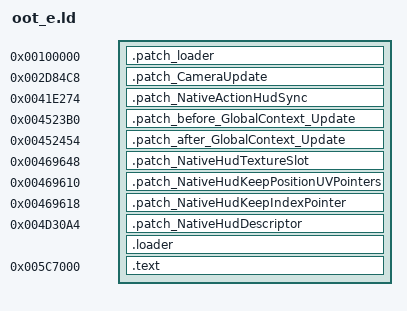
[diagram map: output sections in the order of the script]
OUTPUT_FORMAT("elf32-littlearm", "elf32-littlearm", "elf32-littlearm")
OUTPUT_ARCH(arm)
ENTRY(loader_patch)
SECTIONS
{
	. = 0x100000;
	.patch_loader 0x100000 : {
		*(.patch_loader)
	}

	.patch_CameraUpdate 0x2D84C8 : {
	    * (.patch_CameraUpdate)
	}

	.patch_NativeActionHudSync 0x41E274 : {
		*(.patch_NativeActionHudSync)
	}

	.patch_before_GlobalContext_Update 0x4523B0 : {
		*(.patch_before_GlobalContext_Update)
	}

	.patch_after_GlobalContext_Update 0x452454 : {
		*(.patch_after_GlobalContext_Update)
	}

	.patch_NativeHudTextureSlot 0x469648 : {
		*(.patch_NativeHudTextureSlot)
	}

	.patch_NativeHudKeepPositionUVPointers 0x469610 : {
		*(.patch_NativeHudKeepPositionUVPointers)
	}

	.patch_NativeHudKeepIndexPointer 0x469618 : {
		*(.patch_NativeHudKeepIndexPointer)
	}

	.patch_NativeHudDescriptor 0x4D30A4 : {
		*(.patch_NativeHudDescriptor)
	}

	. = 0x4C99A8;
	. = ALIGN(4);
	.loader : {
		*(.loader*)
	}

	. = 0x005C7000;
	.text : {
		__text_start = . ;
		*(.text)
		*(.text.*)
		__text_end  = . ;
		*(.rodata)
		*(.rodata.*)
		*(.data)
		*(.bss)
		*(COMMON)
	}

	/DISCARD/ : {
		*(.eh_frame*)
		*(.ARM.exidx*)
		*(.ARM.extab*)
	}
}
